# LPC55S16 register map
Vendor: nxp.com; File version: 1.0
CPU: CM33 r2p0, little endian, MPU, FPU, VTOR, 3 interrupt priority bits
Registers are 32-bit, read-write, reset 0x0 unless marked. A register's access mark holds for its fields unless they carry their own. Offsets are from the block's base; [hi:lo] are bit positions; {n}, {i} and the like mark numbered series; 'fields as' and 'values as' point back to an identical list.

## FLASH_CMPA
Base 0x0003E400
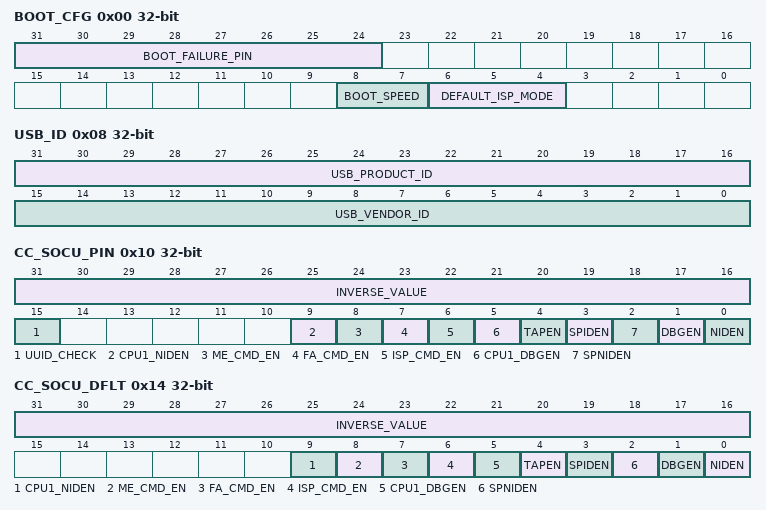
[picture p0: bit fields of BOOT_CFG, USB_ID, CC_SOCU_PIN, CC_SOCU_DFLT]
0x00 BOOT_CFG
  [31:24] BOOT_FAILURE_PIN — GPIO port and pin number to use for indicating failure reason. The toggle rate of the pin is used to decode the error type. [2:0] - Defines GPIO port [7:3] - Defines GPIO pin
  [8:7] BOOT_SPEED — Core clock:
    0=Defined by NMPA.SYSTEM_SPEED_CODE; 1=48MHz FRO; 2=96MHz FRO
  [6:4] DEFAULT_ISP_MODE
    0=Auto ISP; 1=USB_HID_MSC; 2=SPI Slave ISP; 3=I2C Slave ISP; 7=Disable ISP fall through
0x04 SPI_FLASH_CFG
  [4:0] SPI_RECOVERY_BOOT_EN — SPI flash recovery boot is enabled, if non-zero value is written to this field.
0x08 USB_ID
  [31:16] USB_PRODUCT_ID, [15:0] USB_VENDOR_ID
0x0C SDIO_CFG
  [31:0] FIELD
0x10 CC_SOCU_PIN
  [31:16] INVERSE_VALUE — inverse value of bits [15:0]
  [15] UUID_CHECK — Enforce UUID match during Debug authentication.
  [9] CPU1_NIDEN — CPU1 (Micro cortex M33) non-invasive debug enable
    0=Use DAP to enable; 1=Fixed state
  [8] ME_CMD_EN — Flash Mass Erase Command enable
    0=Use DAP to enable; 1=Fixed state
  [7] FA_CMD_EN — FA Command enable
    0=Use DAP to enable; 1=Fixed state
  [6] ISP_CMD_EN — ISP Boot Command enable
    0=Use DAP to enable; 1=Fixed state
  [5] CPU1_DBGEN — CPU1 (Micro cortex M33) invasive debug enable
    0=Use DAP to enable; 1=Fixed state
  [4] TAPEN — JTAG TAP enable
    0=Use DAP to enable; 1=Fixed state
  [3] SPIDEN — Secure invasive debug enable
    0=Use DAP to enable; 1=Fixed state
  [2] SPNIDEN — Secure non-invasive debug enable
    0=Use DAP to enable; 1=Fixed state
  [1] DBGEN — Non Secure debug enable
    0=Use DAP to enable; 1=Fixed state
  [0] NIDEN — Non Secure non-invasive debug enable
    0=Use DAP to enable; 1=Fixed state
0x14 CC_SOCU_DFLT
  [31:16] INVERSE_VALUE — inverse value of bits [15:0]
  [9] CPU1_NIDEN — CPU1 (Micro cortex M33) non-invasive debug fixed state
    0=DISABLE; 1=ENABLE
  [8] ME_CMD_EN — Flash Mass Erase Command fixed state
    0=DISABLE; 1=ENABLE
  [7] FA_CMD_EN — FA Command fixed state
    0=DISABLE; 1=ENABLE
  [6] ISP_CMD_EN — ISP Boot Command fixed state
    0=DISABLE; 1=ENABLE
  [5] CPU1_DBGEN — CPU1 (Micro cortex M33) invasive debug fixed state
    0=DISABLE; 1=ENABLE
  [4] TAPEN — JTAG TAP fixed state
    0=DISABLE; 1=ENABLE
  [3] SPIDEN — Secure invasive debug fixed state
    0=DISABLE; 1=ENABLE
  [2] SPNIDEN — Secure non-invasive debug fixed state
    0=DISABLE; 1=ENABLE
  [1] DBGEN — Non Secure debug fixed state
    0=DISABLE; 1=ENABLE
  [0] NIDEN — Non Secure non-invasive debug fixed state
    0=DISABLE; 1=ENABLE
0x18 VENDOR_USAGE
  [31:16] VENDOR_USAGE — Upper 16 bits of vendor usage field defined in DAP. Lower 16-bits come from customer field area.
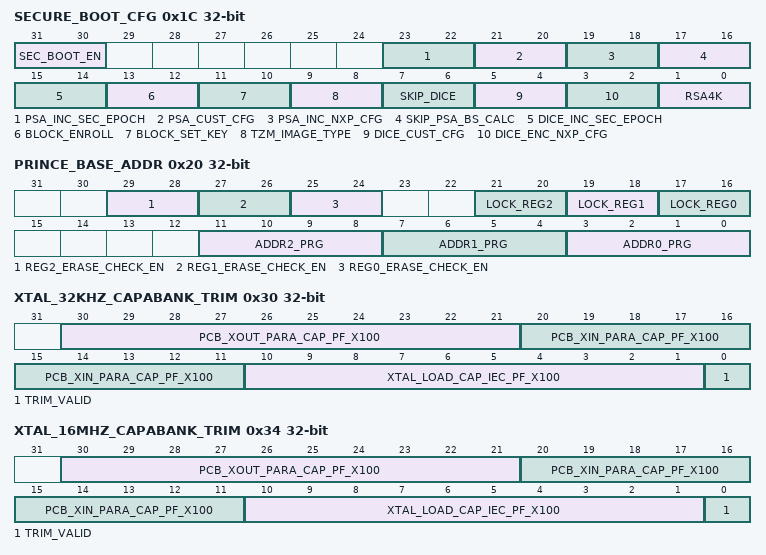
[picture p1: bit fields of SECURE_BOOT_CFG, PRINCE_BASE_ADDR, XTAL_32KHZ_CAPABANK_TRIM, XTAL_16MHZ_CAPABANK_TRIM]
0x1C SECURE_BOOT_CFG
  [31:30] SEC_BOOT_EN — Secure boot enable. 00 - Plain image (internal flash with or without CRC) 01, 10, 11 - Boot signed images. (internal flash, RSA signed)
  [23:22] PSA_INC_SEC_EPOCH — Include security EPOCH in PSA and PSA_boot state computation as per PSA specification.
  [21:20] PSA_CUST_CFG — Include Customer factory area (including keys) in PSA computation.
  [19:18] PSA_INC_NXP_CFG — Include NXP area in PSA computation.
  [17:16] SKIP_PSA_BS_CALC — Skip PSA boot state calculation computation.
  [15:14] DICE_INC_SEC_EPOCH — Include security EPOCH in DICE
  [13:12] BLOCK_ENROLL — Block PUF enrollement. 00 - Enable enrollment mode 01, 10, 11 - Disable further enrollmnet
  [11:10] BLOCK_SET_KEY — Block PUF key code generation. 00 - Enable Key code generation 01, 10, 11 - Disable key code generation
  [9:8] TZM_IMAGE_TYPE — TrustZone-M mode. 00 - TZM mode in image header. 01 - Disable TZ-M. Boots to NonSecure. 10 - TZ-M enable boots to secure mode. 11 - Preset TZM checker from image header.
  [7:6] SKIP_DICE — Skip DICE computation. 00 - Enable DICE 01,10,11 - Disable DICE
  [5:4] DICE_CUST_CFG — Include Customer factory area (including keys) in DICE computation. 00 - not included 01, 10, 11 - included
  [3:2] DICE_ENC_NXP_CFG — Include NXP area in DICE computation. 00 - not included 01, 10, 11 - included
  [1:0] RSA4K — Use RSA4096 keys only. 00- RSA2048 keys 01, 10, 11 - RSA4096 keys
0x20 PRINCE_BASE_ADDR
  [29:28] REG2_ERASE_CHECK_EN — For PRINCE region2 enable checking whether all encrypted pages are erased together. 00 - Check is disabled. 01, 10, 11 - Check is enabled.
  [27:26] REG1_ERASE_CHECK_EN — For PRINCE region1 enable checking whether all encrypted pages are erased together. 00 - Check is disabled. 01, 10, 11 - Check is enabled.
  [25:24] REG0_ERASE_CHECK_EN — For PRINCE region0 enable checking whether all encrypted pages are erased together. 00 - Check is disabled. 01, 10, 11 - Check is enabled.
  [21:20] LOCK_REG2 — Lock PRINCE region2 settings. 00 - Region is not locked. 01, 10, 11 - Region is locked.
  [19:18] LOCK_REG1 — Lock PRINCE region1 settings. 00 - Region is not locked. 01, 10, 11 - Region is locked.
  [17:16] LOCK_REG0 — Lock PRINCE region0 settings. 00 - Region is not locked. 01, 10, 11 - Region is locked.
  [11:8] ADDR2_PRG — Programmable portion of the base address of region 2.
  [7:4] ADDR1_PRG — Programmable portion of the base address of region 1.
  [3:0] ADDR0_PRG — Programmable portion of the base address of region 0.
{0x24+4i} PRINCE_SR_{i} (i=0..2) — Region {i}, sub-region enable
  [31:0] FIELD
0x30 XTAL_32KHZ_CAPABANK_TRIM — Xtal 32kHz capabank triming.
  [30:21] PCB_XOUT_PARA_CAP_PF_X100 — PCB XOUT parasitic capacitance, pF x 100. For example, 6pF becomes 600.
  [20:11] PCB_XIN_PARA_CAP_PF_X100 — PCB XIN parasitic capacitance, pF x 100. For example, 6pF becomes 600.
  [10:1] XTAL_LOAD_CAP_IEC_PF_X100 — Load capacitance, pF x 100. For example, 6pF becomes 600.
  [0] TRIM_VALID — 0 : Capa Bank trimmings not valid. Default trimmings value are used. 1 : Capa Bank trimmings valid.
0x34 XTAL_16MHZ_CAPABANK_TRIM — Xtal 16MHz capabank triming.
  fields as XTAL_32KHZ_CAPABANK_TRIM
0x38 FLASH_REMAP_SIZE — This 32-bit register contains the size of the image to remap, in bytes. The 12 LSBs are ignored, so the size granularity is 4KB.
0x3C FLASH_REMAP_OFFSET — This 32-bit register contains the offset by which the image is to be remapped. The 12 LSBs are ignored, so the remap granularity is 4KB.
{0x50+4i} ROTKH[{i}] (i=0..7) — ROTKH0 for Root of Trust Keys Table hash[255:224] ROTKH1 for Root of Trust Keys Table hash[223:192] ROTKH2 for Root of Trust Keys Table hash[191:160] ROTKH3 for Root of Trust Keys Table hash[159:128] ROTKH4 for Root of Trust Keys Table hash[127:96] ROTKH5 for Root of Trust Keys Table hash[95:64] ROTKH6 for Root of Trust Keys Table hash[63:32] ROTKH7 for Root of Trust Keys Table hash[31:0]
  [31:0] FIELD
{0x100+4i} CUSTOMER_DEFINED[{i}] (i=0..55) — Customer Defined (Programable through ROM API)
  [31:0] FIELD
{0x1E0+4i} SHA256_DIGEST[{i}] (i=0..7) — SHA256_DIGEST0 for DIGEST[31:0] SHA256_DIGEST1 for DIGEST[63:32] SHA256_DIGEST2 for DIGEST[95:64] SHA256_DIGEST3 for DIGEST[127:96] SHA256_DIGEST4 for DIGEST[159:128] SHA256_DIGEST5 for DIGEST[191:160] SHA256_DIGEST6 for DIGEST[223:192] SHA256_DIGEST7 for DIGEST[255:224]
  [31:0] FIELD

## Notices in the file
Copyright 2016-2019 NXP
All rights reserved.
SPDX-License-Identifier: BSD-3-Clause
